# STM32F105 register map
File version: 1.3
CPU: CM3 r1p1, little endian, no MPU, no FPU, 4 interrupt priority bits
Registers are 32-bit, read-write, reset 0x0 unless marked. A register's access mark holds for its fields unless they carry their own. Offsets are from the block's base; [hi:lo] are bit positions; {n}, {i} and the like mark numbered series.

## AFIO — Alternate function I/O
Base 0x40010000
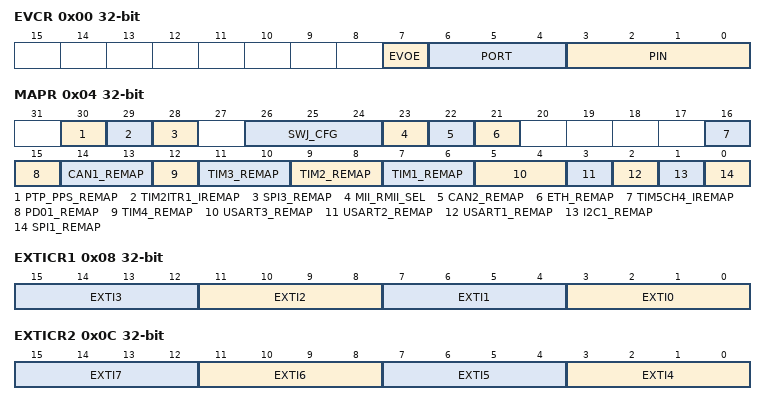
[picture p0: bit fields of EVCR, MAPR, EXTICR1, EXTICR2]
0x00 EVCR — Event Control Register (AFIO_EVCR)
  [7] EVOE — Event Output Enable
  [6:4] PORT — Port selection
  [3:0] PIN — Pin selection
0x04 MAPR access per field — AF remap and debug I/O configuration register (AFIO_MAPR)
  [30] PTP_PPS_REMAP rw — Ethernet PTP PPS remapping
  [29] TIM2ITR1_IREMAP rw — TIM2 internal trigger 1 remapping
  [28] SPI3_REMAP rw — SPI3/I2S3 remapping
  [26:24] SWJ_CFG wo — Serial wire JTAG configuration
  [23] MII_RMII_SEL rw — MII or RMII selection
  [22] CAN2_REMAP rw — CAN2 I/O remapping
  [21] ETH_REMAP rw — Ethernet MAC I/O remapping
  [16] TIM5CH4_IREMAP rw — Set and cleared by software
  [15] PD01_REMAP rw — Port D0/Port D1 mapping on OSCIN/OSCOUT
  [14:13] CAN1_REMAP rw — CAN1 remapping
  [12] TIM4_REMAP rw — TIM4 remapping
  [11:10] TIM3_REMAP rw — TIM3 remapping
  [9:8] TIM2_REMAP rw — TIM2 remapping
  [7:6] TIM1_REMAP rw — TIM1 remapping
  [5:4] USART3_REMAP rw — USART3 remapping
  [3] USART2_REMAP rw — USART2 remapping
  [2] USART1_REMAP rw — USART1 remapping
  [1] I2C1_REMAP rw — I2C1 remapping
  [0] SPI1_REMAP rw — SPI1 remapping
0x08 EXTICR1 — External interrupt configuration register 1 (AFIO_EXTICR1)
  [4n+3:4n] EXTI{n} (n=0..3) — EXTI{n} configuration
0x0C EXTICR2 — External interrupt configuration register 2 (AFIO_EXTICR2)
  [4n-13:4n-16] EXTI{n} (n=4..7) — EXTI{n} configuration
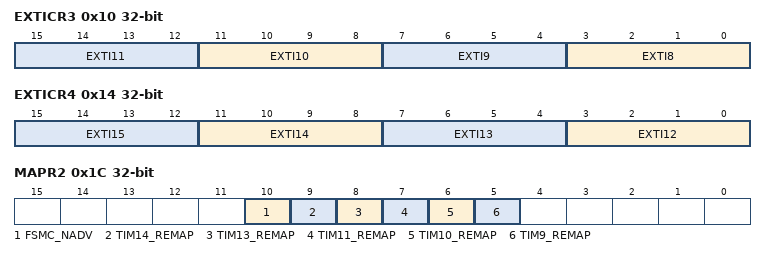
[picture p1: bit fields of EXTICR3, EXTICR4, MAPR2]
0x10 EXTICR3 — External interrupt configuration register 3 (AFIO_EXTICR3)
  [4n-29:4n-32] EXTI{n} (n=8..11) — EXTI{n} configuration
0x14 EXTICR4 — External interrupt configuration register 4 (AFIO_EXTICR4)
  [4n-45:4n-48] EXTI{n} (n=12..15) — EXTI{n} configuration
0x1C MAPR2 — AF remap and debug I/O configuration register
  [10] FSMC_NADV — NADV connect/disconnect
  [9] TIM14_REMAP — TIM14 remapping
  [8] TIM13_REMAP — TIM13 remapping
  [7] TIM11_REMAP — TIM11 remapping
  [6] TIM10_REMAP — TIM10 remapping
  [5] TIM9_REMAP — TIM9 remapping

## BKP — Backup registers
Base 0x40006C00
{0x0+4i} DR{i} (i=1..10) — Backup data register (BKP_DR)
  [15:0] D{i} — Backup data
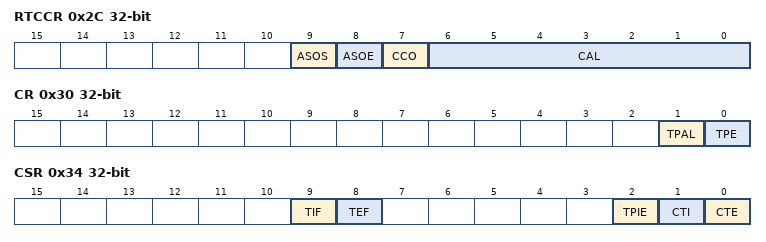
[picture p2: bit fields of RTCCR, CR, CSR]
0x2C RTCCR — RTC clock calibration register (BKP_RTCCR)
  [9] ASOS — Alarm or second output selection
  [8] ASOE — Alarm or second output enable
  [7] CCO — Calibration Clock Output
  [6:0] CAL — Calibration value
0x30 CR — Backup control register (BKP_CR)
  [1] TPAL — Tamper pin active level
  [0] TPE — Tamper pin enable
0x34 CSR access per field — BKP_CSR control/status register (BKP_CSR)
  [9] TIF ro — Tamper Interrupt Flag
  [8] TEF ro — Tamper Event Flag
  [2] TPIE rw — Tamper Pin interrupt enable
  [1] CTI wo — Clear Tamper Interrupt
  [0] CTE wo — Clear Tamper event
{0x14+4i} DR{i} (i=11..13) — Backup data register (BKP_DR)
  [15:0] DR{i} — Backup data
{0x14+4i} DR{i} (i=14..42) — Backup data register (BKP_DR)
  [15:0] D{i} — Backup data

## CAN2 — Controller area network
Base 0x40006800
Same registers: CAN1 0x40006400
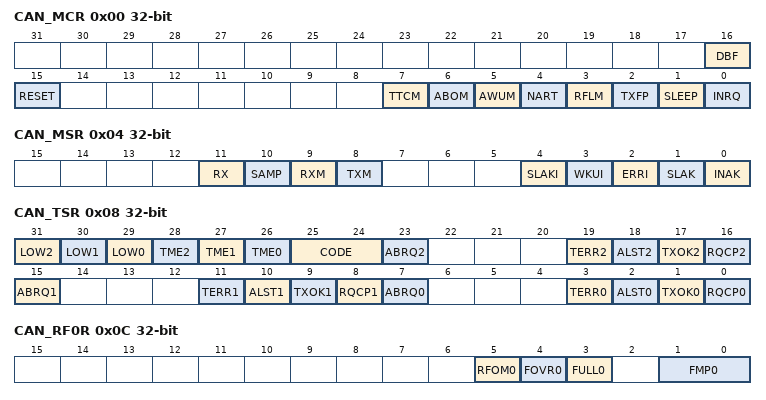
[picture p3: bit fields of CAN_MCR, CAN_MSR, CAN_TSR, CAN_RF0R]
0x00 CAN_MCR
  [16] DBF, [15] RESET, [7] TTCM, [6] ABOM, [5] AWUM, [4] NART, [3] RFLM, [2] TXFP, [1] SLEEP, [0] INRQ
0x04 CAN_MSR access per field
  [11] RX ro, [10] SAMP ro, [9] RXM ro, [8] TXM ro, [4] SLAKI rw, [3] WKUI rw, [2] ERRI rw, [1] SLAK ro, [0] INAK ro
0x08 CAN_TSR access per field
  [31] LOW2 ro — Lowest priority flag for mailbox 2
  [30] LOW1 ro — Lowest priority flag for mailbox 1
  [29] LOW0 ro — Lowest priority flag for mailbox 0
  [28] TME2 ro — Lowest priority flag for mailbox 2
  [27] TME1 ro — Lowest priority flag for mailbox 1
  [26] TME0 ro — Lowest priority flag for mailbox 0
  [25:24] CODE ro
  [23] ABRQ2 rw
  [19] TERR2 rw
  [18] ALST2 rw
  [17] TXOK2 rw
  [16] RQCP2 rw
  [15] ABRQ1 rw
  [11] TERR1 rw
  [10] ALST1 rw
  [9] TXOK1 rw
  [8] RQCP1 rw
  [7] ABRQ0 rw
  [3] TERR0 rw
  [2] ALST0 rw
  [1] TXOK0 rw
  [0] RQCP0 rw
0x0C CAN_RF0R access per field
  [5] RFOM0 rw, [4] FOVR0 rw, [3] FULL0 rw, [1:0] FMP0 ro
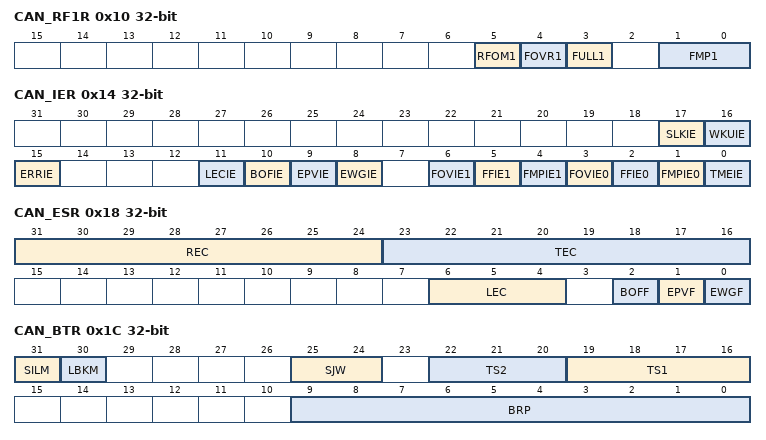
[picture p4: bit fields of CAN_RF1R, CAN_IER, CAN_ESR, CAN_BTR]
0x10 CAN_RF1R access per field
  [5] RFOM1 rw, [4] FOVR1 rw, [3] FULL1 rw, [1:0] FMP1 ro
0x14 CAN_IER
  [17] SLKIE, [16] WKUIE, [15] ERRIE, [11] LECIE, [10] BOFIE, [9] EPVIE, [8] EWGIE, [6] FOVIE1, [5] FFIE1, [4] FMPIE1, [3] FOVIE0, [2] FFIE0, [1] FMPIE0, [0] TMEIE
0x18 CAN_ESR access per field
  [31:24] REC ro, [23:16] TEC ro, [6:4] LEC rw, [2] BOFF ro, [1] EPVF ro, [0] EWGF ro
0x1C CAN_BTR
  [31] SILM, [30] LBKM, [25:24] SJW, [22:20] TS2, [19:16] TS1, [9:0] BRP
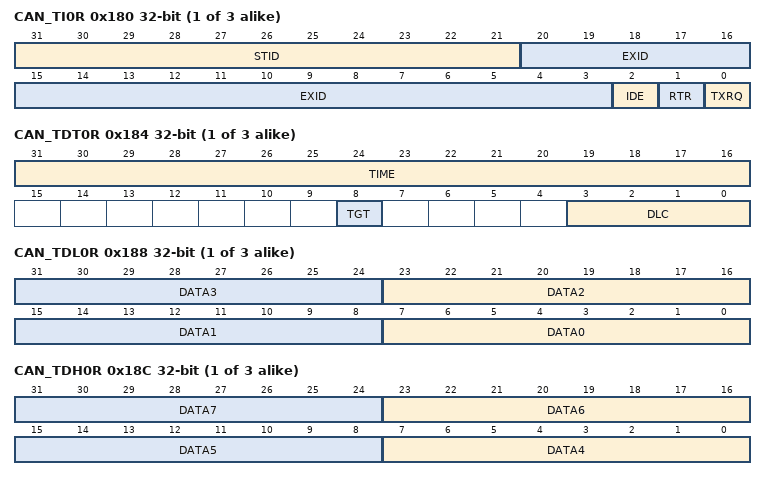
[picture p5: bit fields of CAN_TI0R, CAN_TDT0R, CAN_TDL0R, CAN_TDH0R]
{0x180+0x10*i} CAN_TI{i}R (i=0..2)
  [31:21] STID, [20:3] EXID, [2] IDE, [1] RTR, [0] TXRQ
{0x184+0x10*i} CAN_TDT{i}R (i=0..2)
  [31:16] TIME, [8] TGT, [3:0] DLC
{0x188+0x10*i} CAN_TDL{i}R (i=0..2)
  [8n+7:8n] DATA{n} (n=0..3)
{0x18C+0x10*i} CAN_TDH{i}R (i=0..2)
  [8n-25:8n-32] DATA{n} (n=4..7)
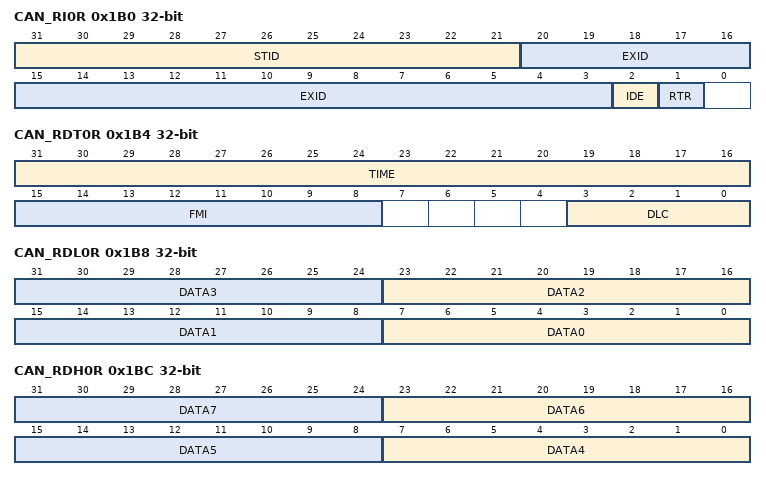
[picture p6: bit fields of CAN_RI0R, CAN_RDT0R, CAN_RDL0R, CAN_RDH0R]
0x1B0 CAN_RI0R ro
  [31:21] STID, [20:3] EXID, [2] IDE, [1] RTR
0x1B4 CAN_RDT0R ro
  [31:16] TIME, [15:8] FMI, [3:0] DLC
0x1B8 CAN_RDL0R ro
  [8n+7:8n] DATA{n} (n=0..3)
0x1BC CAN_RDH0R ro
  [8n-25:8n-32] DATA{n} (n=4..7)
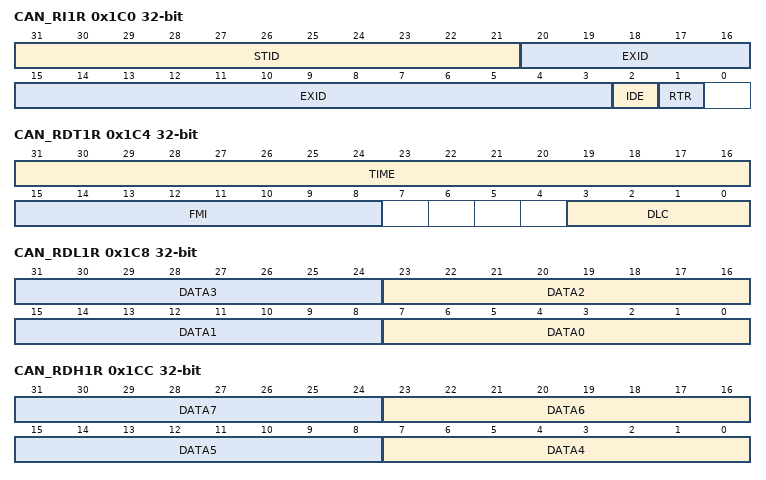
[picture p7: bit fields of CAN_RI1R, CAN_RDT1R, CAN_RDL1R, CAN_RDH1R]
0x1C0 CAN_RI1R ro
  [31:21] STID, [20:3] EXID, [2] IDE, [1] RTR
0x1C4 CAN_RDT1R ro
  [31:16] TIME, [15:8] FMI, [3:0] DLC
0x1C8 CAN_RDL1R ro
  [8n+7:8n] DATA{n} (n=0..3)
0x1CC CAN_RDH1R ro
  [8n-25:8n-32] DATA{n} (n=4..7)
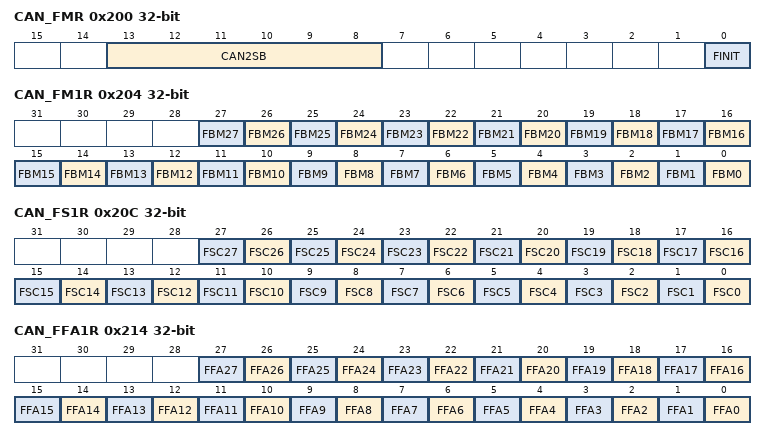
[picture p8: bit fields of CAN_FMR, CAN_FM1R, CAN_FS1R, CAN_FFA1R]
0x200 CAN_FMR
  [13:8] CAN2SB, [0] FINIT
0x204 CAN_FM1R
  [n] FBM{n} (n=0..27) — Filter mode
0x20C CAN_FS1R
  [n] FSC{n} (n=0..27) — Filter scale configuration
0x214 CAN_FFA1R
  [n] FFA{n} (n=0..27) — Filter FIFO assignment for filter {n}
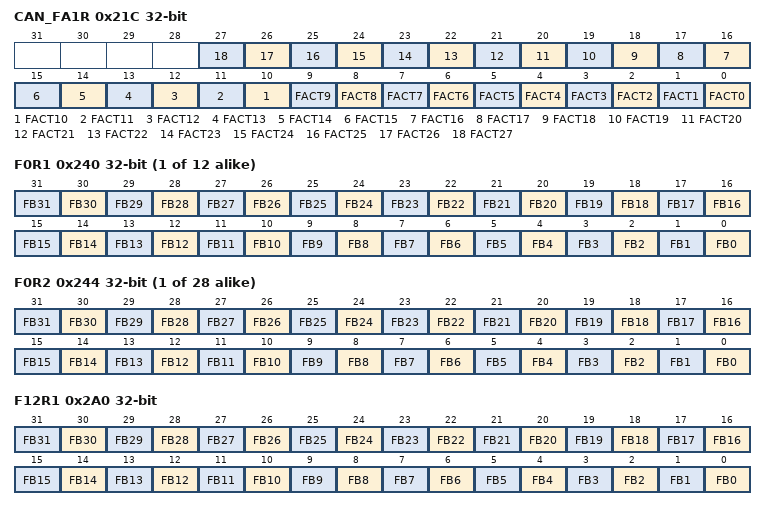
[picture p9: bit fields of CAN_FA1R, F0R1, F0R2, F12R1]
0x21C CAN_FA1R
  [n] FACT{n} (n=0..27) — Filter active
{0x240+8i} F{i}R1 (i=0..11) — Filter bank {i} register 1
  [n] FB{n} (n=0..31) — Filter bits
{0x244+8i} F{i}R2 (i=0..27) — Filter bank {i} register 2
  [n] FB{n} (n=0..31) — Filter bits
0x2A0 F12R1 — Filter bank 4 register 1
  [n] FB{n} (n=0..31) — Filter bits
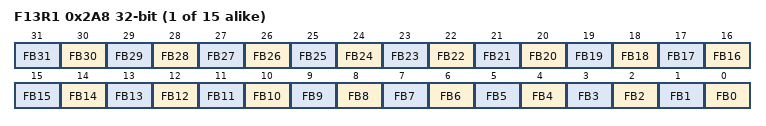
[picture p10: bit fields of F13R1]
{0x240+8i} F{i}R1 (i=13..27) — Filter bank {i} register 1
  [n] FB{n} (n=0..31) — Filter bits

## Notices in the file
Copyright (c) 2024 STMicroelectronics.
SPDX-License-Identifier: Apache-2.0
Licensed under the Apache License, Version 2.0 (the "License");
you may not use this file except in compliance with the License.
You may obtain a copy of the License at
http://www.apache.org/licenses/LICENSE-2.0
Unless required by applicable law or agreed to in writing, software
distributed under the License is distributed on an "AS IS" BASIS,
WITHOUT WARRANTIES OR CONDITIONS OF ANY KIND, either express or implied.
See the License for the specific language governing permissions and
limitations under the License.
